# jbr_MDR1986VE1T register map
Registers are 32-bit, access not given, no defined reset value unless marked. A register's access mark holds for its fields unless they carry their own. Addresses are absolute; registers are grouped by the start of their names; [hi:lo] are bit positions; {n}, {i} and the like mark numbered series; 'fields as' and 'values as' point back to an identical list.

## RTC
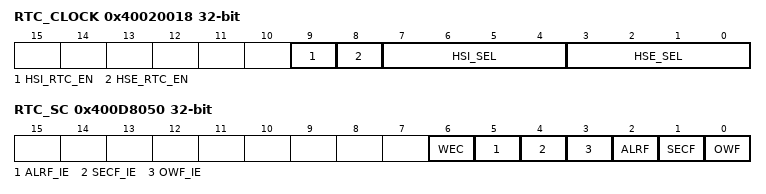
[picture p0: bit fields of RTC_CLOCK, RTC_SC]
0x40020018 RTC_CLOCK
  [9] HSI_RTC_EN, [8] HSE_RTC_EN, [7:4] HSI_SEL, [3:0] HSE_SEL
0x400D8040 RTC_CNT
0x400D8044 RTC_DIV
  [19:0] RTC_DIV
0x400D8048 RTC_PRL
  [19:0] RTC_PRL
0x400D804C RTC_ALRM
0x400D8050 RTC_SC
  [6] WEC, [5] ALRF_IE, [4] SECF_IE, [3] OWF_IE, [2] ALRF, [1] SECF, [0] OWF

## ETH
0x30000000 ETH_Dilimiter 16-bit
0x30000002 ETH_MAC_T 16-bit
0x30000004 ETH_MAC_M 16-bit
0x30000006 ETH_MAC_H 16-bit
{0x30000008+2i} ETH_HASH{i} 16-bit (i=0..3)
0x30000010 ETH_IPG 16-bit
0x30000012 ETH_PSC 16-bit
0x30000014 ETH_BAG 16-bit
0x30000016 ETH_JitterWnd 16-bit
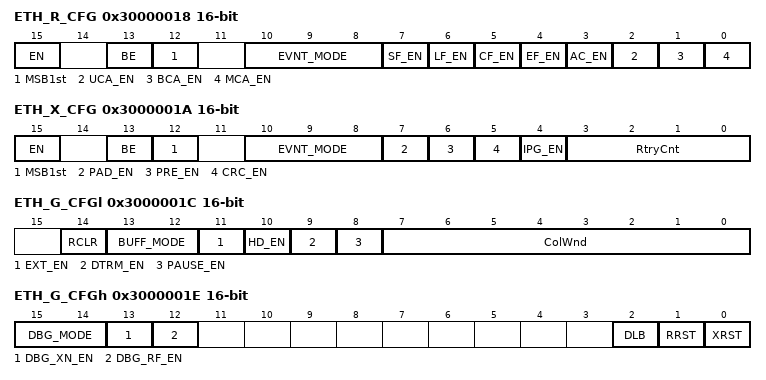
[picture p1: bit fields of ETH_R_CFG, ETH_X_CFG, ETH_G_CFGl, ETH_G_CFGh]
0x30000018 ETH_R_CFG 16-bit
  [15] EN, [13] BE, [12] MSB1st, [10:8] EVNT_MODE, [7] SF_EN, [6] LF_EN, [5] CF_EN, [4] EF_EN, [3] AC_EN, [2] UCA_EN, [1] BCA_EN, [0] MCA_EN
0x3000001A ETH_X_CFG 16-bit
  [15] EN, [13] BE, [12] MSB1st, [10:8] EVNT_MODE, [7] PAD_EN, [6] PRE_EN, [5] CRC_EN, [4] IPG_EN, [3:0] RtryCnt
0x3000001C ETH_G_CFGl 16-bit
  [14] RCLR, [13:12] BUFF_MODE, [11] EXT_EN, [10] HD_EN, [9] DTRM_EN, [8] PAUSE_EN, [7:0] ColWnd
0x3000001E ETH_G_CFGh 16-bit
  [15:14] DBG_MODE, [13] DBG_XN_EN, [12] DBG_RF_EN, [2] DLB, [1] RRST, [0] XRST
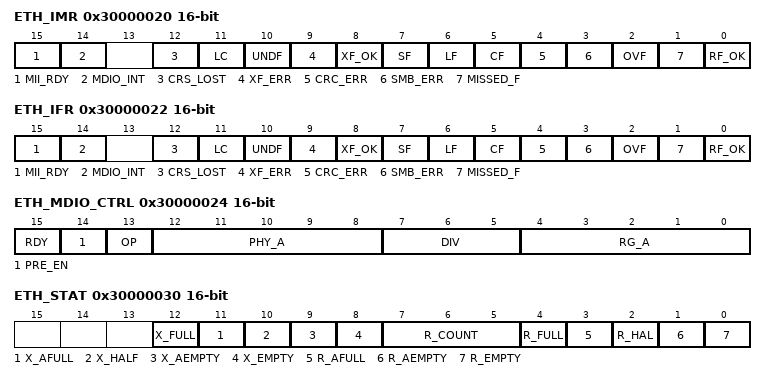
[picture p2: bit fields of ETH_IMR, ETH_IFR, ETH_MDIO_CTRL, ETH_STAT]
0x30000020 ETH_IMR 16-bit
  [15] MII_RDY, [14] MDIO_INT, [12] CRS_LOST, [11] LC, [10] UNDF, [9] XF_ERR, [8] XF_OK, [7] SF, [6] LF, [5] CF, [4] CRC_ERR, [3] SMB_ERR, [2] OVF, [1] MISSED_F, [0] RF_OK
0x30000022 ETH_IFR 16-bit
  fields as ETH_IMR
0x30000024 ETH_MDIO_CTRL 16-bit
  [15] RDY, [14] PRE_EN, [13] OP, [12:8] PHY_A, [7:5] DIV, [4:0] RG_A
0x30000026 ETH_MDIO_DATA 16-bit
0x30000028 ETH_R_Head 16-bit
0x3000002A ETH_X_Tail 16-bit
0x3000002C ETH_R_Tail 16-bit
0x3000002E ETH_X_Head 16-bit
0x30000030 ETH_STAT 16-bit
  [12] X_FULL, [11] X_AFULL, [10] X_HALF, [9] X_AEMPTY, [8] X_EMPTY, [7:5] R_COUNT, [4] R_FULL, [3] R_AFULL, [2] R_HAL, [1] R_AEMPTY, [0] R_EMPTY
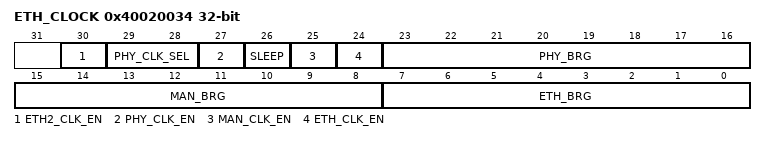
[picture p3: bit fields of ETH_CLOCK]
0x40020034 ETH_CLOCK
  [30] ETH2_CLK_EN, [29:28] PHY_CLK_SEL, [27] PHY_CLK_EN, [26] SLEEP, [25] MAN_CLK_EN, [24] ETH_CLK_EN, [23:16] PHY_BRG, [15:8] MAN_BRG, [7:0] ETH_BRG

## BKP
{0x400D8000+4i} BKP_REG_{i:02} (i=0..9)
0x400D8028 BKP_REG_0A
0x400D802C BKP_REG_0B
0x400D8030 BKP_REG_0C
0x400D8034 BKP_REG_0D
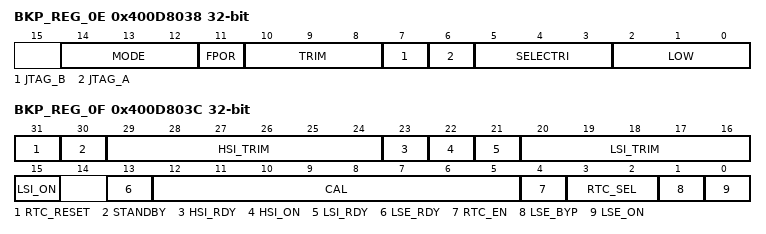
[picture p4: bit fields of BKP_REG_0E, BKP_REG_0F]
0x400D8038 BKP_REG_0E
  [14:12] MODE, [11] FPOR, [10:8] TRIM, [7] JTAG_B, [6] JTAG_A, [5:3] SELECTRI, [2:0] LOW
0x400D803C BKP_REG_0F
  [31] RTC_RESET, [30] STANDBY, [29:24] HSI_TRIM, [23] HSI_RDY, [22] HSI_ON, [21] LSI_RDY, [20:16] LSI_TRIM, [15] LSI_ON, [13] LSE_RDY, [12:5] CAL, [4] RTC_EN, [3:2] RTC_SEL, [1] LSE_BYP, [0] LSE_ON

## RAM
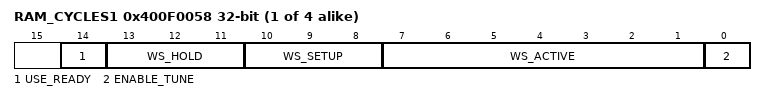
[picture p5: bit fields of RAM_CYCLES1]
{0x400F0054+4i} RAM_CYCLES{i} (i=1..4)
  [14] USE_READY, [13:11] WS_HOLD, [10:8] WS_SETUP, [7:1] WS_ACTIVE, [0] ENABLE_TUNE

## CAN1
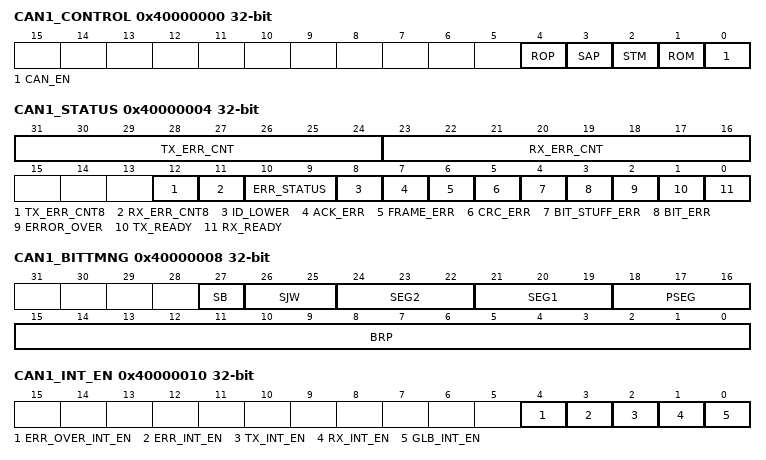
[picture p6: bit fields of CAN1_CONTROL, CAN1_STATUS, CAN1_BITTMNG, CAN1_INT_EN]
0x40000000 CAN1_CONTROL
  [4] ROP, [3] SAP, [2] STM, [1] ROM, [0] CAN_EN
0x40000004 CAN1_STATUS
  [31:24] TX_ERR_CNT, [23:16] RX_ERR_CNT, [12] TX_ERR_CNT8, [11] RX_ERR_CNT8, [10:9] ERR_STATUS, [8] ID_LOWER, [7] ACK_ERR, [6] FRAME_ERR, [5] CRC_ERR, [4] BIT_STUFF_ERR, [3] BIT_ERR, [2] ERROR_OVER, [1] TX_READY, [0] RX_READY
0x40000008 CAN1_BITTMNG
  [27] SB, [26:25] SJW, [24:22] SEG2, [21:19] SEG1, [18:16] PSEG, [15:0] BRP
0x40000010 CAN1_INT_EN
  [4] ERR_OVER_INT_EN, [3] ERR_INT_EN, [2] TX_INT_EN, [1] RX_INT_EN, [0] GLB_INT_EN
0x4000001C CAN1_OVER
  [7:0] ERROR_MAX
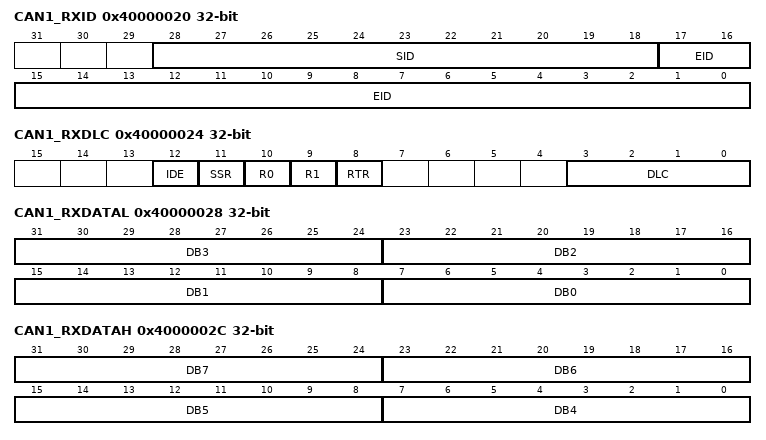
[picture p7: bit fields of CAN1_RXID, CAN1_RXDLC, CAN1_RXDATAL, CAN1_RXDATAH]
0x40000020 CAN1_RXID
  [28:18] SID, [17:0] EID
0x40000024 CAN1_RXDLC
  [12] IDE, [11] SSR, [10] R0, [9] R1, [8] RTR, [3:0] DLC
0x40000028 CAN1_RXDATAL
  [8n+7:8n] DB{n} (n=0..3)
0x4000002C CAN1_RXDATAH
  [8n-25:8n-32] DB{n} (n=4..7)
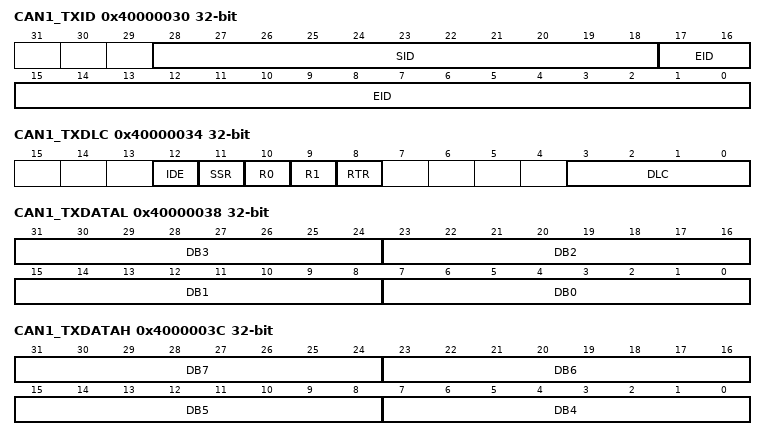
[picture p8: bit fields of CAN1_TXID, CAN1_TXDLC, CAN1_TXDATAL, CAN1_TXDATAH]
0x40000030 CAN1_TXID
  [28:18] SID, [17:0] EID
0x40000034 CAN1_TXDLC
  [12] IDE, [11] SSR, [10] R0, [9] R1, [8] RTR, [3:0] DLC
0x40000038 CAN1_TXDATAL
  [8n+7:8n] DB{n} (n=0..3)
0x4000003C CAN1_TXDATAH
  [8n-25:8n-32] DB{n} (n=4..7)
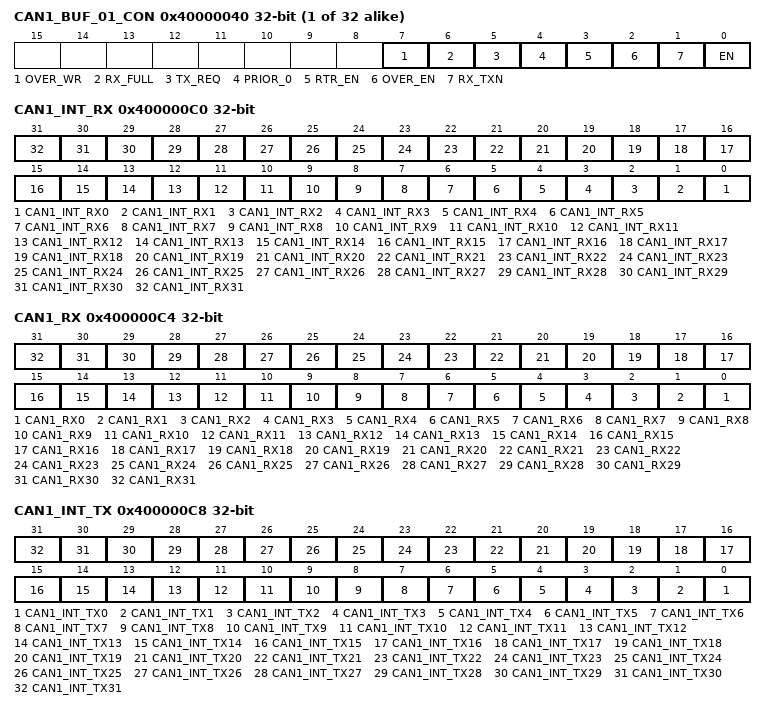
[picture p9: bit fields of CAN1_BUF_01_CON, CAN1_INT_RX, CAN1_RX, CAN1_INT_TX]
{0x4000003C+4i} CAN1_BUF_{i:02}_CON (i=1..32)
  [7] OVER_WR, [6] RX_FULL, [5] TX_REQ, [4] PRIOR_0, [3] RTR_EN, [2] OVER_EN, [1] RX_TXN, [0] EN
0x400000C0 CAN1_INT_RX
  [n] CAN1_INT_RX{n} (n=0..31)
0x400000C4 CAN1_RX
  [n] CAN1_RX{n} (n=0..31)
0x400000C8 CAN1_INT_TX
  [n] CAN1_INT_TX{n} (n=0..31)
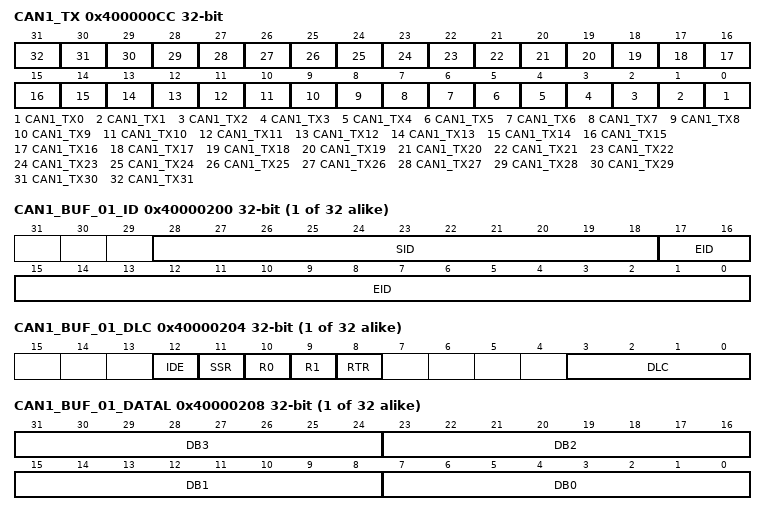
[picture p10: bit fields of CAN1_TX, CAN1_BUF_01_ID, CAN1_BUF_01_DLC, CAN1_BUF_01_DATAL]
0x400000CC CAN1_TX
  [n] CAN1_TX{n} (n=0..31)
{0x400001F0+0x10*i} CAN1_BUF_{i:02}_ID (i=1..32)
  [28:18] SID, [17:0] EID
{0x400001F4+0x10*i} CAN1_BUF_{i:02}_DLC (i=1..32)
  [12] IDE, [11] SSR, [10] R0, [9] R1, [8] RTR, [3:0] DLC
{0x400001F8+0x10*i} CAN1_BUF_{i:02}_DATAL (i=1..32)
  [8n+7:8n] DB{n} (n=0..3)
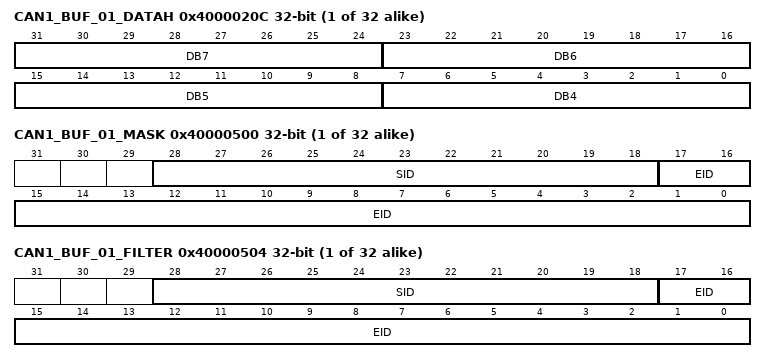
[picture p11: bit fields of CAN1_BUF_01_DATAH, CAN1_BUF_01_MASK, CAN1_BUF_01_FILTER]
{0x400001FC+0x10*i} CAN1_BUF_{i:02}_DATAH (i=1..32)
  [8n-25:8n-32] DB{n} (n=4..7)
{0x400004F8+8i} CAN1_BUF_{i:02}_MASK (i=1..32)
  [28:18] SID, [17:0] EID
{0x400004FC+8i} CAN1_BUF_{i:02}_FILTER (i=1..32)
  [28:18] SID, [17:0] EID
